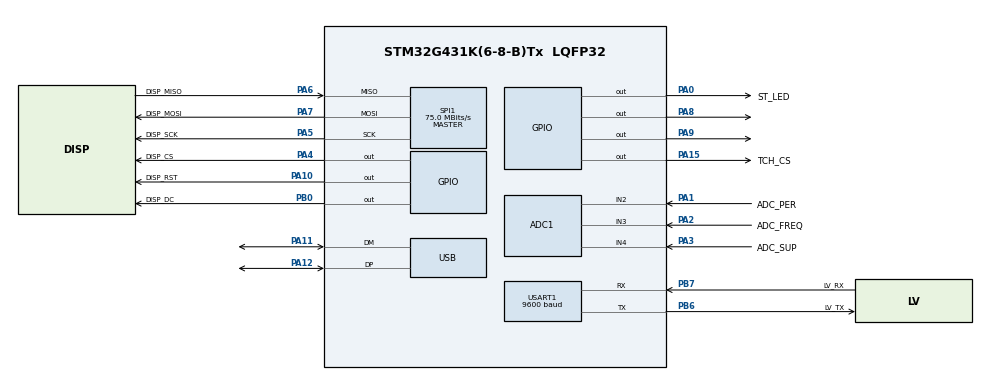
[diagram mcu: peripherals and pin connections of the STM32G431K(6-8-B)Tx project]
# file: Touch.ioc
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ADC1.Channel-0\#ChannelRegularConversion=ADC_CHANNEL_2
ADC1.Channel-1\#ChannelRegularConversion=ADC_CHANNEL_3
ADC1.Channel-2\#ChannelRegularConversion=ADC_CHANNEL_4
ADC1.ClockPrescaler=ADC_CLOCK_ASYNC_DIV12
ADC1.ContinuousConvMode=DISABLE
ADC1.DMAContinuousRequests=ENABLE
ADC1.EOCSelection=ADC_EOC_SEQ_CONV
ADC1.NbrOfConversion=3
ADC1.NbrOfConversionFlag=1
ADC1.OffsetNumber-0\#ChannelRegularConversion=ADC_OFFSET_NONE
ADC1.OffsetNumber-1\#ChannelRegularConversion=ADC_OFFSET_NONE
ADC1.OffsetNumber-2\#ChannelRegularConversion=ADC_OFFSET_NONE
ADC1.Overrun=ADC_OVR_DATA_OVERWRITTEN
ADC1.Rank-0\#ChannelRegularConversion=1
ADC1.Rank-1\#ChannelRegularConversion=2
ADC1.Rank-2\#ChannelRegularConversion=3
ADC1.SamplingTime-0\#ChannelRegularConversion=ADC_SAMPLETIME_47CYCLES_5
ADC1.SamplingTime-1\#ChannelRegularConversion=ADC_SAMPLETIME_47CYCLES_5
ADC1.SamplingTime-2\#ChannelRegularConversion=ADC_SAMPLETIME_47CYCLES_5
ADC1.master=1
Dma.ADC1.1.Direction=DMA_PERIPH_TO_MEMORY
Dma.ADC1.1.EventEnable=DISABLE
Dma.ADC1.1.Instance=DMA1_Channel1
Dma.ADC1.1.MemDataAlignment=DMA_MDATAALIGN_HALFWORD
Dma.ADC1.1.MemInc=DMA_MINC_ENABLE
Dma.ADC1.1.Mode=DMA_CIRCULAR
Dma.ADC1.1.PeriphDataAlignment=DMA_PDATAALIGN_HALFWORD
Dma.ADC1.1.PeriphInc=DMA_PINC_DISABLE
Dma.ADC1.1.Polarity=HAL_DMAMUX_REQ_GEN_RISING
Dma.ADC1.1.Priority=DMA_PRIORITY_LOW
Dma.ADC1.1.RequestNumber=1
Dma.ADC1.1.SignalID=NONE
Dma.ADC1.1.SyncEnable=DISABLE
Dma.ADC1.1.SyncPolarity=HAL_DMAMUX_SYNC_NO_EVENT
Dma.ADC1.1.SyncRequestNumber=1
Dma.ADC1.1.SyncSignalID=NONE
Dma.Request0=SPI1_TX
Dma.Request1=ADC1
Dma.Request2=USART1_TX
Dma.Request3=USART1_RX
Dma.SPI1_TX.0.Direction=DMA_MEMORY_TO_PERIPH
Dma.SPI1_TX.0.EventEnable=DISABLE
Dma.SPI1_TX.0.Instance=DMA1_Channel2
Dma.SPI1_TX.0.MemDataAlignment=DMA_MDATAALIGN_BYTE
Dma.SPI1_TX.0.MemInc=DMA_MINC_ENABLE
Dma.SPI1_TX.0.Mode=DMA_NORMAL
Dma.SPI1_TX.0.PeriphDataAlignment=DMA_PDATAALIGN_BYTE
Dma.SPI1_TX.0.PeriphInc=DMA_PINC_DISABLE
Dma.SPI1_TX.0.Polarity=HAL_DMAMUX_REQ_GEN_RISING
Dma.SPI1_TX.0.Priority=DMA_PRIORITY_LOW
Dma.SPI1_TX.0.RequestNumber=1
Dma.SPI1_TX.0.SignalID=NONE
Dma.SPI1_TX.0.SyncEnable=DISABLE
Dma.SPI1_TX.0.SyncPolarity=HAL_DMAMUX_SYNC_NO_EVENT
Dma.SPI1_TX.0.SyncRequestNumber=1
Dma.SPI1_TX.0.SyncSignalID=NONE
Dma.USART1_RX.3.Direction=DMA_PERIPH_TO_MEMORY
Dma.USART1_RX.3.EventEnable=DISABLE
Dma.USART1_RX.3.Instance=DMA1_Channel4
Dma.USART1_RX.3.MemDataAlignment=DMA_MDATAALIGN_BYTE
Dma.USART1_RX.3.MemInc=DMA_MINC_ENABLE
Dma.USART1_RX.3.Mode=DMA_NORMAL
Dma.USART1_RX.3.PeriphDataAlignment=DMA_PDATAALIGN_BYTE
Dma.USART1_RX.3.PeriphInc=DMA_PINC_DISABLE
Dma.USART1_RX.3.Polarity=HAL_DMAMUX_REQ_GEN_RISING
Dma.USART1_RX.3.Priority=DMA_PRIORITY_LOW
Dma.USART1_RX.3.RequestNumber=1
Dma.USART1_RX.3.SignalID=NONE
Dma.USART1_RX.3.SyncEnable=DISABLE
Dma.USART1_RX.3.SyncPolarity=HAL_DMAMUX_SYNC_NO_EVENT
Dma.USART1_RX.3.SyncRequestNumber=1
Dma.USART1_RX.3.SyncSignalID=NONE
Dma.USART1_TX.2.Direction=DMA_MEMORY_TO_PERIPH
Dma.USART1_TX.2.EventEnable=DISABLE
Dma.USART1_TX.2.Instance=DMA1_Channel3
Dma.USART1_TX.2.MemDataAlignment=DMA_MDATAALIGN_BYTE
Dma.USART1_TX.2.MemInc=DMA_MINC_ENABLE
Dma.USART1_TX.2.Mode=DMA_NORMAL
Dma.USART1_TX.2.PeriphDataAlignment=DMA_PDATAALIGN_BYTE
Dma.USART1_TX.2.PeriphInc=DMA_PINC_DISABLE
Dma.USART1_TX.2.Polarity=HAL_DMAMUX_REQ_GEN_RISING
Dma.USART1_TX.2.Priority=DMA_PRIORITY_LOW
Dma.USART1_TX.2.RequestNumber=1
Dma.USART1_TX.2.SignalID=NONE
Dma.USART1_TX.2.SyncEnable=DISABLE
Dma.USART1_TX.2.SyncPolarity=HAL_DMAMUX_SYNC_NO_EVENT
Dma.USART1_TX.2.SyncRequestNumber=1
Dma.USART1_TX.2.SyncSignalID=NONE
Mcu.Family=STM32G4
Mcu.Name=STM32G431K(6-8-B)Tx
Mcu.Package=LQFP32
NVIC.DMA1_Channel1_IRQn=true\:0\:0\:false\:false\:true\:false\:true\:true
NVIC.DMA1_Channel2_IRQn=true\:0\:0\:false\:false\:true\:false\:true\:true
NVIC.DMA1_Channel3_IRQn=true\:0\:0\:false\:false\:true\:false\:true\:true
NVIC.DMA1_Channel4_IRQn=true\:0\:0\:false\:false\:true\:false\:true\:true
NVIC.PriorityGroup=NVIC_PRIORITYGROUP_4
NVIC.TIM2_IRQn=true\:0\:0\:false\:false\:true\:true\:true\:true
NVIC.USB_LP_IRQn=true\:0\:0\:false\:false\:true\:false\:true\:true
PA0.GPIO_Label=ST_LED
PA0.Signal=GPIO_Output
PA1.GPIO_Label=ADC_PER
PA1.Mode=IN2-Single-Ended
PA1.Signal=ADC1_IN2
PA10.GPIO_Label=DISP_RST
PA10.Signal=GPIO_Output
PA11.Mode=Device
PA11.Signal=USB_DM
PA12.Mode=Device
PA12.Signal=USB_DP
PA13.GPIO_Label=SWDIO
PA13.Mode=Serial_Wire
PA13.Signal=SYS_JTMS-SWDIO
PA14.GPIO_Label=SWCLK
PA14.Mode=Serial_Wire
PA14.Signal=SYS_JTCK-SWCLK
PA15.GPIO_Label=TCH_CS
PA15.Signal=GPIO_Output
PA2.GPIO_Label=ADC_FREQ
PA2.Mode=IN3-Single-Ended
PA2.Signal=ADC1_IN3
PA3.GPIO_Label=ADC_SUP
PA3.Mode=IN4-Single-Ended
PA3.Signal=ADC1_IN4
PA4.GPIO_Label=DISP_CS
PA4.Signal=GPIO_Output
PA5.GPIO_Label=DISP_SCK
PA5.GPIO_Speed=GPIO_SPEED_FREQ_MEDIUM
PA5.Mode=Full_Duplex_Master
PA5.Signal=SPI1_SCK
PA6.GPIO_Label=DISP_MISO
PA6.GPIO_Speed=GPIO_SPEED_FREQ_LOW
PA6.Mode=Full_Duplex_Master
PA6.Signal=SPI1_MISO
PA7.GPIO_Label=DISP_MOSI
PA7.GPIO_Speed=GPIO_SPEED_FREQ_MEDIUM
PA7.Mode=Full_Duplex_Master
PA7.Signal=SPI1_MOSI
PA8.Signal=GPIO_Output
PA9.Signal=GPIO_Output
PB0.GPIO_Label=DISP_DC
PB0.Signal=GPIO_Output
PB6.GPIO_Label=LV_TX
PB6.Mode=Asynchronous
PB6.Signal=USART1_TX
PB7.GPIO_Label=LV_RX
PB7.Mode=Asynchronous
PB7.Signal=USART1_RX
PF0-OSC_IN.Mode=HSE-External-Oscillator
PF0-OSC_IN.Signal=RCC_OSC_IN
PF1-OSC_OUT.Mode=HSE-External-Oscillator
PF1-OSC_OUT.Signal=RCC_OSC_OUT
ProjectManager.HeapSize=0x200
ProjectManager.StackSize=0x400
ProjectManager.TargetToolchain=STM32CubeIDE
RCC.ADC12CLockSelection=RCC_ADC12CLKSOURCE_PLL
RCC.ADC12Freq_Value=15000000
RCC.AHBFreq_Value=150000000
RCC.APB1Freq_Value=150000000
RCC.APB1TimFreq_Value=150000000
RCC.APB2Freq_Value=150000000
RCC.APB2TimFreq_Value=150000000
RCC.CK48CLockSelection=RCC_USBCLKSOURCE_HSI48
RCC.CortexFreq_Value=150000000
RCC.EXTERNAL_CLOCK_VALUE=12288000
RCC.HCLKFreq_Value=150000000
RCC.HSE_VALUE=20000000
RCC.HSI48_VALUE=48000000
RCC.HSI_VALUE=16000000
RCC.LSE_VALUE=32768
RCC.PLLM=RCC_PLLM_DIV5
RCC.PLLN=75
RCC.PLLP=RCC_PLLP_DIV20
RCC.PLLQ=RCC_PLLQ_DIV6
RCC.PLLSourceVirtual=RCC_PLLSOURCE_HSE
RCC.RCC_MCO1Source=RCC_MCO1SOURCE_SYSCLK
RCC.SYSCLKFreq_VALUE=150000000
RCC.SYSCLKSource=RCC_SYSCLKSOURCE_PLLCLK
RCC.USBFreq_Value=48000000
RCC.VCOOutputFreq_Value=300000000
SPI1.BaudRatePrescaler=SPI_BAUDRATEPRESCALER_2
SPI1.CalculateBaudRate=75.0 MBits/s
SPI1.DataSize=SPI_DATASIZE_8BIT
SPI1.Direction=SPI_DIRECTION_2LINES
SPI1.Mode=SPI_MODE_MASTER
SPI1.VirtualType=VM_MASTER
TIM2.PeriodNoDither=199
TIM2.Prescaler=149
USART1.BaudRate=9600
USART1.VirtualMode-Asynchronous=VM_ASYNC
USB_DEVICE.CLASS_NAME_FS=CDC
USB_DEVICE.VirtualMode=Cdc
USB_DEVICE.VirtualModeFS=Cdc_FS
VP_SYS_VS_DBSignals.Mode=DisableDeadBatterySignals
VP_TIM2_VS_ClockSourceINT.Mode=Internal
VP_USB_DEVICE_VS_USB_DEVICE_CDC_FS.Mode=CDC_FS
board=custom

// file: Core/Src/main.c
/* USER CODE BEGIN Header */
/**
  ******************************************************************************
  * @file           : main.c
  * @brief          : Main program body
  ******************************************************************************
  * @attention
  *
  * Copyright (c) 2025 STMicroelectronics.
  * All rights reserved.
  *
  * This software is licensed under terms that can be found in the LICENSE file
  * in the root directory of this software component.
  * If no LICENSE file comes with this software, it is provided AS-IS.
  *
  ******************************************************************************
  */
/* USER CODE END Header */
#include "main.h"
#include "usb_device.h"

/* USER CODE BEGIN Includes */
#include "hmi.h"
/* USER CODE END Includes */

/* USER CODE BEGIN PD */
//#define ADC_CHANNEL_COUNT 3
//volatile uint16_t adc_buffer[ADC_CHANNEL_COUNT];

/* USER CODE END PD */

void SystemClock_Config(void);
static void MX_GPIO_Init(void);
static void MX_DMA_Init(void);
static void MX_ADC1_Init(void);
static void MX_SPI1_Init(void);
static void MX_TIM2_Init(void);
static void MX_USART1_UART_Init(void);

int main(void)
{

  /* MCU Configuration--------------------------------------------------------*/

  /* Reset of all peripherals, Initializes the Flash interface and the Systick. */
  HAL_Init();

  /* Configure the system clock */
  SystemClock_Config();

  /* Initialize all configured peripherals */
  MX_GPIO_Init();
  MX_DMA_Init();
  MX_ADC1_Init();
  MX_SPI1_Init();
  MX_TIM2_Init();
  MX_USB_Device_Init();
  MX_USART1_UART_Init();

  /* Infinite loop */
  /* USER CODE BEGIN WHILE */
  while (1)
  {
	hmi_main();
    /* USER CODE END WHILE */

  }
}

void SystemClock_Config(void)
{
  LL_FLASH_SetLatency(LL_FLASH_LATENCY_4);
  while(LL_FLASH_GetLatency() != LL_FLASH_LATENCY_4)
  {
  }
  LL_PWR_SetRegulVoltageScaling(LL_PWR_REGU_VOLTAGE_SCALE1);
  LL_RCC_HSE_Enable();
   /* Wait till HSE is ready */
  while(LL_RCC_HSE_IsReady() != 1)
  {
  }

  LL_RCC_HSI48_Enable();
   /* Wait till HSI48 is ready */
  while(LL_RCC_HSI48_IsReady() != 1)
  {
  }

  LL_RCC_PLL_ConfigDomain_SYS(LL_RCC_PLLSOURCE_HSE, LL_RCC_PLLM_DIV_5, 75, LL_RCC_PLLR_DIV_2);
  LL_RCC_PLL_ConfigDomain_ADC(LL_RCC_PLLSOURCE_HSE, LL_RCC_PLLM_DIV_5, 75, LL_RCC_PLLP_DIV_20);
  LL_RCC_PLL_EnableDomain_SYS();
  LL_RCC_PLL_EnableDomain_ADC();
  LL_RCC_PLL_Enable();
   /* Wait till PLL is ready */
  while(LL_RCC_PLL_IsReady() != 1)
  {
  }

  LL_RCC_SetSysClkSource(LL_RCC_SYS_CLKSOURCE_PLL);
  LL_RCC_SetAHBPrescaler(LL_RCC_SYSCLK_DIV_2);
   /* Wait till System clock is ready */
  while(LL_RCC_GetSysClkSource() != LL_RCC_SYS_CLKSOURCE_STATUS_PLL)
  {
  }

  /* Insure 1us transition state at intermediate medium speed clock*/
  for (__IO uint32_t i = (170 >> 1); i !=0; i--);

  /* Set AHB prescaler*/
  LL_RCC_SetAHBPrescaler(LL_RCC_SYSCLK_DIV_1);
  LL_RCC_SetAPB1Prescaler(LL_RCC_APB1_DIV_1);
  LL_RCC_SetAPB2Prescaler(LL_RCC_APB2_DIV_1);
  LL_SetSystemCoreClock(150000000);

   /* Update the time base */
  if (HAL_InitTick (TICK_INT_PRIORITY) != HAL_OK)
  {
    Error_Handler();
  }
}

static void MX_ADC1_Init(void)
{

  LL_ADC_InitTypeDef ADC_InitStruct = {0};
  LL_ADC_REG_InitTypeDef ADC_REG_InitStruct = {0};
  LL_ADC_CommonInitTypeDef ADC_CommonInitStruct = {0};

  LL_GPIO_InitTypeDef GPIO_InitStruct = {0};

  LL_RCC_SetADCClockSource(LL_RCC_ADC12_CLKSOURCE_PLL);

  /* Peripheral clock enable */
  LL_AHB2_GRP1_EnableClock(LL_AHB2_GRP1_PERIPH_ADC12);

  LL_AHB2_GRP1_EnableClock(LL_AHB2_GRP1_PERIPH_GPIOA);
  /**ADC1 GPIO Configuration
  PA1   ------> ADC1_IN2
  PA2   ------> ADC1_IN3
  PA3   ------> ADC1_IN4
  */
  GPIO_InitStruct.Pin = ADC_PER_Pin;
  GPIO_InitStruct.Mode = LL_GPIO_MODE_ANALOG;
  GPIO_InitStruct.Pull = LL_GPIO_PULL_NO;
  LL_GPIO_Init(ADC_PER_GPIO_Port, &GPIO_InitStruct);

  GPIO_InitStruct.Pin = ADC_FREQ_Pin;
  GPIO_InitStruct.Mode = LL_GPIO_MODE_ANALOG;
  GPIO_InitStruct.Pull = LL_GPIO_PULL_NO;
  LL_GPIO_Init(ADC_FREQ_GPIO_Port, &GPIO_InitStruct);

  GPIO_InitStruct.Pin = ADC_SUP_Pin;
  GPIO_InitStruct.Mode = LL_GPIO_MODE_ANALOG;
  GPIO_InitStruct.Pull = LL_GPIO_PULL_NO;
  LL_GPIO_Init(ADC_SUP_GPIO_Port, &GPIO_InitStruct);

  /* ADC1 DMA Init */

  /* ADC1 Init */
  LL_DMA_SetPeriphRequest(DMA1, LL_DMA_CHANNEL_1, LL_DMAMUX_REQ_ADC1);

  LL_DMA_SetDataTransferDirection(DMA1, LL_DMA_CHANNEL_1, LL_DMA_DIRECTION_PERIPH_TO_MEMORY);

  LL_DMA_SetChannelPriorityLevel(DMA1, LL_DMA_CHANNEL_1, LL_DMA_PRIORITY_LOW);

  LL_DMA_SetMode(DMA1, LL_DMA_CHANNEL_1, LL_DMA_MODE_CIRCULAR);

  LL_DMA_SetPeriphIncMode(DMA1, LL_DMA_CHANNEL_1, LL_DMA_PERIPH_NOINCREMENT);

  LL_DMA_SetMemoryIncMode(DMA1, LL_DMA_CHANNEL_1, LL_DMA_MEMORY_INCREMENT);

  LL_DMA_SetPeriphSize(DMA1, LL_DMA_CHANNEL_1, LL_DMA_PDATAALIGN_HALFWORD);

  LL_DMA_SetMemorySize(DMA1, LL_DMA_CHANNEL_1, LL_DMA_MDATAALIGN_HALFWORD);

  /** Common config
  */
  ADC_InitStruct.Resolution = LL_ADC_RESOLUTION_12B;
  ADC_InitStruct.DataAlignment = LL_ADC_DATA_ALIGN_RIGHT;
  ADC_InitStruct.LowPowerMode = LL_ADC_LP_MODE_NONE;
  LL_ADC_Init(ADC1, &ADC_InitStruct);
  ADC_REG_InitStruct.TriggerSource = LL_ADC_REG_TRIG_SOFTWARE;
  ADC_REG_InitStruct.SequencerLength = LL_ADC_REG_SEQ_SCAN_ENABLE_3RANKS;
  ADC_REG_InitStruct.SequencerDiscont = LL_ADC_REG_SEQ_DISCONT_DISABLE;
  ADC_REG_InitStruct.ContinuousMode = LL_ADC_REG_CONV_SINGLE;
  ADC_REG_InitStruct.DMATransfer = LL_ADC_REG_DMA_TRANSFER_UNLIMITED;
  ADC_REG_InitStruct.Overrun = LL_ADC_REG_OVR_DATA_OVERWRITTEN;
  LL_ADC_REG_Init(ADC1, &ADC_REG_InitStruct);
  LL_ADC_SetGainCompensation(ADC1, 0);
  LL_ADC_SetOverSamplingScope(ADC1, LL_ADC_OVS_DISABLE);
  ADC_CommonInitStruct.CommonClock = LL_ADC_CLOCK_ASYNC_DIV12;
  ADC_CommonInitStruct.Multimode = LL_ADC_MULTI_INDEPENDENT;
  LL_ADC_CommonInit(__LL_ADC_COMMON_INSTANCE(ADC1), &ADC_CommonInitStruct);

  /* Disable ADC deep power down (enabled by default after reset state) */
  LL_ADC_DisableDeepPowerDown(ADC1);
  /* Enable ADC internal voltage regulator */
  LL_ADC_EnableInternalRegulator(ADC1);
  /* Delay for ADC internal voltage regulator stabilization. */
  /* Compute number of CPU cycles to wait for, from delay in us. */
  /* Note: Variable divided by 2 to compensate partially */
  /* CPU processing cycles (depends on compilation optimization). */
  /* Note: If system core clock frequency is below 200kHz, wait time */
  /* is only a few CPU processing cycles. */
  uint32_t wait_loop_index;
  wait_loop_index = ((LL_ADC_DELAY_INTERNAL_REGUL_STAB_US * (SystemCoreClock / (100000 * 2))) / 10);
  while(wait_loop_index != 0)
  {
    wait_loop_index--;
  }

  /** Configure Regular Channel
  */
  LL_ADC_REG_SetSequencerRanks(ADC1, LL_ADC_REG_RANK_1, LL_ADC_CHANNEL_2);
  LL_ADC_SetChannelSamplingTime(ADC1, LL_ADC_CHANNEL_2, LL_ADC_SAMPLINGTIME_47CYCLES_5);
  LL_ADC_SetChannelSingleDiff(ADC1, LL_ADC_CHANNEL_2, LL_ADC_SINGLE_ENDED);

  /** Configure Regular Channel
  */
  LL_ADC_REG_SetSequencerRanks(ADC1, LL_ADC_REG_RANK_2, LL_ADC_CHANNEL_3);
  LL_ADC_SetChannelSamplingTime(ADC1, LL_ADC_CHANNEL_3, LL_ADC_SAMPLINGTIME_47CYCLES_5);
  LL_ADC_SetChannelSingleDiff(ADC1, LL_ADC_CHANNEL_3, LL_ADC_SINGLE_ENDED);

  /** Configure Regular Channel
  */
  LL_ADC_REG_SetSequencerRanks(ADC1, LL_ADC_REG_RANK_3, LL_ADC_CHANNEL_4);
  LL_ADC_SetChannelSamplingTime(ADC1, LL_ADC_CHANNEL_4, LL_ADC_SAMPLINGTIME_47CYCLES_5);
  LL_ADC_SetChannelSingleDiff(ADC1, LL_ADC_CHANNEL_4, LL_ADC_SINGLE_ENDED);

}

static void MX_SPI1_Init(void)
{

  LL_SPI_InitTypeDef SPI_InitStruct = {0};

  LL_GPIO_InitTypeDef GPIO_InitStruct = {0};

  /* Peripheral clock enable */
  LL_APB2_GRP1_EnableClock(LL_APB2_GRP1_PERIPH_SPI1);

  LL_AHB2_GRP1_EnableClock(LL_AHB2_GRP1_PERIPH_GPIOA);
  /**SPI1 GPIO Configuration
  PA5   ------> SPI1_SCK
  PA6   ------> SPI1_MISO
  PA7   ------> SPI1_MOSI
  */
  GPIO_InitStruct.Pin = DISP_SCK_Pin;
  GPIO_InitStruct.Mode = LL_GPIO_MODE_ALTERNATE;
  GPIO_InitStruct.Speed = LL_GPIO_SPEED_FREQ_MEDIUM;
  GPIO_InitStruct.OutputType = LL_GPIO_OUTPUT_PUSHPULL;
  GPIO_InitStruct.Pull = LL_GPIO_PULL_NO;
  GPIO_InitStruct.Alternate = LL_GPIO_AF_5;
  LL_GPIO_Init(DISP_SCK_GPIO_Port, &GPIO_InitStruct);

  GPIO_InitStruct.Pin = DISP_MISO_Pin;
  GPIO_InitStruct.Mode = LL_GPIO_MODE_ALTERNATE;
  GPIO_InitStruct.Speed = LL_GPIO_SPEED_FREQ_LOW;
  GPIO_InitStruct.OutputType = LL_GPIO_OUTPUT_PUSHPULL;
  GPIO_InitStruct.Pull = LL_GPIO_PULL_NO;
  GPIO_InitStruct.Alternate = LL_GPIO_AF_5;
  LL_GPIO_Init(DISP_MISO_GPIO_Port, &GPIO_InitStruct);

  GPIO_InitStruct.Pin = DISP_MOSI_Pin;
  GPIO_InitStruct.Mode = LL_GPIO_MODE_ALTERNATE;
  GPIO_InitStruct.Speed = LL_GPIO_SPEED_FREQ_MEDIUM;
  GPIO_InitStruct.OutputType = LL_GPIO_OUTPUT_PUSHPULL;
  GPIO_InitStruct.Pull = LL_GPIO_PULL_NO;
  GPIO_InitStruct.Alternate = LL_GPIO_AF_5;
  LL_GPIO_Init(DISP_MOSI_GPIO_Port, &GPIO_InitStruct);

  /* SPI1 DMA Init */

  /* SPI1_TX Init */
  LL_DMA_SetPeriphRequest(DMA1, LL_DMA_CHANNEL_2, LL_DMAMUX_REQ_SPI1_TX);

  LL_DMA_SetDataTransferDirection(DMA1, LL_DMA_CHANNEL_2, LL_DMA_DIRECTION_MEMORY_TO_PERIPH);

  LL_DMA_SetChannelPriorityLevel(DMA1, LL_DMA_CHANNEL_2, LL_DMA_PRIORITY_LOW);

  LL_DMA_SetMode(DMA1, LL_DMA_CHANNEL_2, LL_DMA_MODE_NORMAL);

  LL_DMA_SetPeriphIncMode(DMA1, LL_DMA_CHANNEL_2, LL_DMA_PERIPH_NOINCREMENT);

  LL_DMA_SetMemoryIncMode(DMA1, LL_DMA_CHANNEL_2, LL_DMA_MEMORY_INCREMENT);

  LL_DMA_SetPeriphSize(DMA1, LL_DMA_CHANNEL_2, LL_DMA_PDATAALIGN_BYTE);

  LL_DMA_SetMemorySize(DMA1, LL_DMA_CHANNEL_2, LL_DMA_MDATAALIGN_BYTE);

  /* SPI1 parameter configuration*/
  SPI_InitStruct.TransferDirection = LL_SPI_FULL_DUPLEX;
  SPI_InitStruct.Mode = LL_SPI_MODE_MASTER;
  SPI_InitStruct.DataWidth = LL_SPI_DATAWIDTH_8BIT;
  SPI_InitStruct.ClockPolarity = LL_SPI_POLARITY_LOW;
  SPI_InitStruct.ClockPhase = LL_SPI_PHASE_1EDGE;
  SPI_InitStruct.NSS = LL_SPI_NSS_SOFT;
  SPI_InitStruct.BaudRate = LL_SPI_BAUDRATEPRESCALER_DIV4;
  SPI_InitStruct.BitOrder = LL_SPI_MSB_FIRST;
  SPI_InitStruct.CRCCalculation = LL_SPI_CRCCALCULATION_DISABLE;
  SPI_InitStruct.CRCPoly = 7;
  LL_SPI_Init(SPI1, &SPI_InitStruct);
  LL_SPI_SetStandard(SPI1, LL_SPI_PROTOCOL_MOTOROLA);
  LL_SPI_EnableNSSPulseMgt(SPI1);

}

static void MX_TIM2_Init(void)
{

  LL_TIM_InitTypeDef TIM_InitStruct = {0};

  /* Peripheral clock enable */
  LL_APB1_GRP1_EnableClock(LL_APB1_GRP1_PERIPH_TIM2);

  /* TIM2 interrupt Init */
  NVIC_SetPriority(TIM2_IRQn, NVIC_EncodePriority(NVIC_GetPriorityGrouping(),0, 0));
  NVIC_EnableIRQ(TIM2_IRQn);

  TIM_InitStruct.Prescaler = 149;
  TIM_InitStruct.CounterMode = LL_TIM_COUNTERMODE_UP;
  TIM_InitStruct.Autoreload = 199;
  TIM_InitStruct.ClockDivision = LL_TIM_CLOCKDIVISION_DIV1;
  LL_TIM_Init(TIM2, &TIM_InitStruct);
  LL_TIM_DisableARRPreload(TIM2);
  LL_TIM_SetClockSource(TIM2, LL_TIM_CLOCKSOURCE_INTERNAL);
  LL_TIM_SetTriggerOutput(TIM2, LL_TIM_TRGO_RESET);
  LL_TIM_DisableMasterSlaveMode(TIM2);

}

static void MX_USART1_UART_Init(void)
{

  LL_USART_InitTypeDef USART_InitStruct = {0};

  LL_GPIO_InitTypeDef GPIO_InitStruct = {0};

  LL_RCC_SetUSARTClockSource(LL_RCC_USART1_CLKSOURCE_PCLK2);

  /* Peripheral clock enable */
  LL_APB2_GRP1_EnableClock(LL_APB2_GRP1_PERIPH_USART1);

  LL_AHB2_GRP1_EnableClock(LL_AHB2_GRP1_PERIPH_GPIOB);
  /**USART1 GPIO Configuration
  PB6   ------> USART1_TX
  PB7   ------> USART1_RX
  */
  GPIO_InitStruct.Pin = LV_TX_Pin;
  GPIO_InitStruct.Mode = LL_GPIO_MODE_ALTERNATE;
  GPIO_InitStruct.Speed = LL_GPIO_SPEED_FREQ_LOW;
  GPIO_InitStruct.OutputType = LL_GPIO_OUTPUT_PUSHPULL;
  GPIO_InitStruct.Pull = LL_GPIO_PULL_NO;
  GPIO_InitStruct.Alternate = LL_GPIO_AF_7;
  LL_GPIO_Init(LV_TX_GPIO_Port, &GPIO_InitStruct);

  GPIO_InitStruct.Pin = LV_RX_Pin;
  GPIO_InitStruct.Mode = LL_GPIO_MODE_ALTERNATE;
  GPIO_InitStruct.Speed = LL_GPIO_SPEED_FREQ_LOW;
  GPIO_InitStruct.OutputType = LL_GPIO_OUTPUT_PUSHPULL;
  GPIO_InitStruct.Pull = LL_GPIO_PULL_NO;
  GPIO_InitStruct.Alternate = LL_GPIO_AF_7;
  LL_GPIO_Init(LV_RX_GPIO_Port, &GPIO_InitStruct);

  /* USART1 DMA Init */

  /* USART1_TX Init */
  LL_DMA_SetPeriphRequest(DMA1, LL_DMA_CHANNEL_3, LL_DMAMUX_REQ_USART1_TX);

  LL_DMA_SetDataTransferDirection(DMA1, LL_DMA_CHANNEL_3, LL_DMA_DIRECTION_MEMORY_TO_PERIPH);

  LL_DMA_SetChannelPriorityLevel(DMA1, LL_DMA_CHANNEL_3, LL_DMA_PRIORITY_LOW);

  LL_DMA_SetMode(DMA1, LL_DMA_CHANNEL_3, LL_DMA_MODE_NORMAL);

  LL_DMA_SetPeriphIncMode(DMA1, LL_DMA_CHANNEL_3, LL_DMA_PERIPH_NOINCREMENT);

  LL_DMA_SetMemoryIncMode(DMA1, LL_DMA_CHANNEL_3, LL_DMA_MEMORY_INCREMENT);

  LL_DMA_SetPeriphSize(DMA1, LL_DMA_CHANNEL_3, LL_DMA_PDATAALIGN_BYTE);

  LL_DMA_SetMemorySize(DMA1, LL_DMA_CHANNEL_3, LL_DMA_MDATAALIGN_BYTE);

  /* USART1_RX Init */
  LL_DMA_SetPeriphRequest(DMA1, LL_DMA_CHANNEL_4, LL_DMAMUX_REQ_USART1_RX);

  LL_DMA_SetDataTransferDirection(DMA1, LL_DMA_CHANNEL_4, LL_DMA_DIRECTION_PERIPH_TO_MEMORY);

  LL_DMA_SetChannelPriorityLevel(DMA1, LL_DMA_CHANNEL_4, LL_DMA_PRIORITY_LOW);

  LL_DMA_SetMode(DMA1, LL_DMA_CHANNEL_4, LL_DMA_MODE_NORMAL);

  LL_DMA_SetPeriphIncMode(DMA1, LL_DMA_CHANNEL_4, LL_DMA_PERIPH_NOINCREMENT);

  LL_DMA_SetMemoryIncMode(DMA1, LL_DMA_CHANNEL_4, LL_DMA_MEMORY_INCREMENT);

  LL_DMA_SetPeriphSize(DMA1, LL_DMA_CHANNEL_4, LL_DMA_PDATAALIGN_BYTE);

  LL_DMA_SetMemorySize(DMA1, LL_DMA_CHANNEL_4, LL_DMA_MDATAALIGN_BYTE);

  USART_InitStruct.PrescalerValue = LL_USART_PRESCALER_DIV1;
  USART_InitStruct.BaudRate = 9600;
  USART_InitStruct.DataWidth = LL_USART_DATAWIDTH_8B;
  USART_InitStruct.StopBits = LL_USART_STOPBITS_1;
  USART_InitStruct.Parity = LL_USART_PARITY_NONE;
  USART_InitStruct.TransferDirection = LL_USART_DIRECTION_TX_RX;
  USART_InitStruct.HardwareFlowControl = LL_USART_HWCONTROL_NONE;
  USART_InitStruct.OverSampling = LL_USART_OVERSAMPLING_16;
  LL_USART_Init(USART1, &USART_InitStruct);
  LL_USART_SetTXFIFOThreshold(USART1, LL_USART_FIFOTHRESHOLD_1_8);
  LL_USART_SetRXFIFOThreshold(USART1, LL_USART_FIFOTHRESHOLD_1_8);
  LL_USART_DisableFIFO(USART1);
  LL_USART_ConfigAsyncMode(USART1);

  LL_USART_Enable(USART1);

  /* Polling USART1 initialisation */
  while((!(LL_USART_IsActiveFlag_TEACK(USART1))) || (!(LL_USART_IsActiveFlag_REACK(USART1))))
  {
  }

}

static void MX_DMA_Init(void)
{

  /* Init with LL driver */
  /* DMA controller clock enable */
  LL_AHB1_GRP1_EnableClock(LL_AHB1_GRP1_PERIPH_DMAMUX1);
  LL_AHB1_GRP1_EnableClock(LL_AHB1_GRP1_PERIPH_DMA1);

  /* DMA interrupt init */
  /* DMA1_Channel1_IRQn interrupt configuration */
  NVIC_SetPriority(DMA1_Channel1_IRQn, NVIC_EncodePriority(NVIC_GetPriorityGrouping(),0, 0));
  NVIC_EnableIRQ(DMA1_Channel1_IRQn);
  /* DMA1_Channel2_IRQn interrupt configuration */
  NVIC_SetPriority(DMA1_Channel2_IRQn, NVIC_EncodePriority(NVIC_GetPriorityGrouping(),0, 0));
  NVIC_EnableIRQ(DMA1_Channel2_IRQn);
  /* DMA1_Channel3_IRQn interrupt configuration */
  NVIC_SetPriority(DMA1_Channel3_IRQn, NVIC_EncodePriority(NVIC_GetPriorityGrouping(),0, 0));
  NVIC_EnableIRQ(DMA1_Channel3_IRQn);
  /* DMA1_Channel4_IRQn interrupt configuration */
  NVIC_SetPriority(DMA1_Channel4_IRQn, NVIC_EncodePriority(NVIC_GetPriorityGrouping(),0, 0));
  NVIC_EnableIRQ(DMA1_Channel4_IRQn);

}

static void MX_GPIO_Init(void)
{
  LL_GPIO_InitTypeDef GPIO_InitStruct = {0};

  /* GPIO Ports Clock Enable */
  LL_AHB2_GRP1_EnableClock(LL_AHB2_GRP1_PERIPH_GPIOF);
  LL_AHB2_GRP1_EnableClock(LL_AHB2_GRP1_PERIPH_GPIOA);
  LL_AHB2_GRP1_EnableClock(LL_AHB2_GRP1_PERIPH_GPIOB);

  /**/
  LL_GPIO_ResetOutputPin(ST_LED_GPIO_Port, ST_LED_Pin);

  /**/
  LL_GPIO_ResetOutputPin(DISP_CS_GPIO_Port, DISP_CS_Pin);

  /**/
  LL_GPIO_ResetOutputPin(DISP_DC_GPIO_Port, DISP_DC_Pin);

  /**/
  LL_GPIO_ResetOutputPin(GPIOA, LL_GPIO_PIN_8);

  /**/
  LL_GPIO_ResetOutputPin(GPIOA, LL_GPIO_PIN_9);

  /**/
  LL_GPIO_ResetOutputPin(DISP_RST_GPIO_Port, DISP_RST_Pin);

  /**/
  LL_GPIO_ResetOutputPin(TCH_CS_GPIO_Port, TCH_CS_Pin);

  /**/
  GPIO_InitStruct.Pin = ST_LED_Pin;
  GPIO_InitStruct.Mode = LL_GPIO_MODE_OUTPUT;
  GPIO_InitStruct.Speed = LL_GPIO_SPEED_FREQ_LOW;
  GPIO_InitStruct.OutputType = LL_GPIO_OUTPUT_PUSHPULL;
  GPIO_InitStruct.Pull = LL_GPIO_PULL_NO;
  LL_GPIO_Init(ST_LED_GPIO_Port, &GPIO_InitStruct);

  /**/
  GPIO_InitStruct.Pin = DISP_CS_Pin;
  GPIO_InitStruct.Mode = LL_GPIO_MODE_OUTPUT;
  GPIO_InitStruct.Speed = LL_GPIO_SPEED_FREQ_LOW;
  GPIO_InitStruct.OutputType = LL_GPIO_OUTPUT_PUSHPULL;
  GPIO_InitStruct.Pull = LL_GPIO_PULL_NO;
  LL_GPIO_Init(DISP_CS_GPIO_Port, &GPIO_InitStruct);

  /**/
  GPIO_InitStruct.Pin = DISP_DC_Pin;
  GPIO_InitStruct.Mode = LL_GPIO_MODE_OUTPUT;
  GPIO_InitStruct.Speed = LL_GPIO_SPEED_FREQ_LOW;
  GPIO_InitStruct.OutputType = LL_GPIO_OUTPUT_PUSHPULL;
  GPIO_InitStruct.Pull = LL_GPIO_PULL_NO;
  LL_GPIO_Init(DISP_DC_GPIO_Port, &GPIO_InitStruct);

  /**/
  GPIO_InitStruct.Pin = LL_GPIO_PIN_8;
  GPIO_InitStruct.Mode = LL_GPIO_MODE_OUTPUT;
  GPIO_InitStruct.Speed = LL_GPIO_SPEED_FREQ_LOW;
  GPIO_InitStruct.OutputType = LL_GPIO_OUTPUT_PUSHPULL;
  GPIO_InitStruct.Pull = LL_GPIO_PULL_NO;
  LL_GPIO_Init(GPIOA, &GPIO_InitStruct);

  /**/
  GPIO_InitStruct.Pin = LL_GPIO_PIN_9;
  GPIO_InitStruct.Mode = LL_GPIO_MODE_OUTPUT;
  GPIO_InitStruct.Speed = LL_GPIO_SPEED_FREQ_LOW;
  GPIO_InitStruct.OutputType = LL_GPIO_OUTPUT_PUSHPULL;
  GPIO_InitStruct.Pull = LL_GPIO_PULL_NO;
  LL_GPIO_Init(GPIOA, &GPIO_InitStruct);

  /**/
  GPIO_InitStruct.Pin = DISP_RST_Pin;
  GPIO_InitStruct.Mode = LL_GPIO_MODE_OUTPUT;
  GPIO_InitStruct.Speed = LL_GPIO_SPEED_FREQ_LOW;
  GPIO_InitStruct.OutputType = LL_GPIO_OUTPUT_PUSHPULL;
  GPIO_InitStruct.Pull = LL_GPIO_PULL_NO;
  LL_GPIO_Init(DISP_RST_GPIO_Port, &GPIO_InitStruct);

  /**/
  GPIO_InitStruct.Pin = TCH_CS_Pin;
  GPIO_InitStruct.Mode = LL_GPIO_MODE_OUTPUT;
  GPIO_InitStruct.Speed = LL_GPIO_SPEED_FREQ_LOW;
  GPIO_InitStruct.OutputType = LL_GPIO_OUTPUT_PUSHPULL;
  GPIO_InitStruct.Pull = LL_GPIO_PULL_NO;
  LL_GPIO_Init(TCH_CS_GPIO_Port, &GPIO_InitStruct);

}

void Error_Handler(void)
{
  __disable_irq();
  while (1)
  {
  }
}
